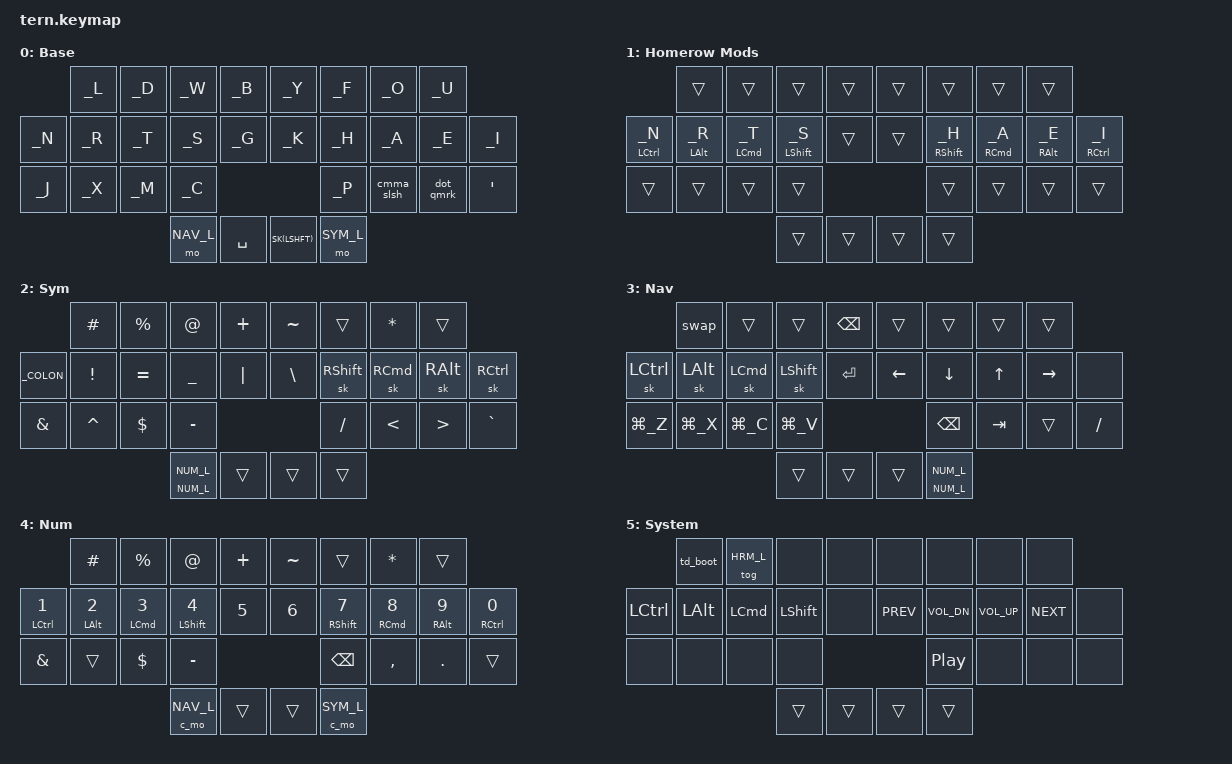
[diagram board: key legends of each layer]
/*
 * Copyright (c) 2022 The ZMK Contributors
 *
 * SPDX-License-Identifier: MIT
 */

#include <behaviors.dtsi>
#include <dt-bindings/zmk/keys.h>

// https://github.com/urob/zmk-auto-layer
#include <behaviors/num_word.dtsi>
&num_word {
  ignore-modifiers;
};

// Use Vallium layout but map it in the OS
#ifndef KEYMAP_DRAWER
#include "locales/keys_vallium.h"
#endif

/* Key positions
    0  1  2  3         4  5  6  7
8  9  10 11 12        13 14 15 16 17
18 19 20 21              22 23 24 25
            26 27  28 29            */

#define KEYS_L 0 1 2 3 8 9 10 11 12 18 19 20 21
#define KEYS_R 4 5 6 7 13 14 15 16 17 22 23 24 25
#define KEYS_T 26 27 28 29

#define DEF_L 0
#define HRM_L 1
#define SYM_L 2
#define NAV_L 3
#define NUM_L 4
#define SYS_L 5

#define NON_SYS_LAYERS DEF_L HRM_L SYM_L NAV_L NUM_L

// How long a key must be pressed to trigger Hold behavior
#define HRM_TERM 280
// If you press a tapped hold-tap again within quick-tap-ms milliseconds of the
// first press, it will always trigger the tap behavior
#define HRM_QUICK_TAP 175
// This effectively disables the hold-tap when typing quickly. As a rule of
// thumb, you want to set it to at least 10500/x where x is your (relaxed) WPM
#define HRM_IDLE (10500 / 50)
#define COMBO_IDLE HRM_IDLE

// Not-so-sticky key, see nk behavior def below
#define SK(KEY) &nk KEY KEY

// Exits num-word
#define CANCEL &kp K_CANCEL

// &lt { flavor = "tap-preferred"; };

&sk {  // sticky-key config
    release-after-ms = <900>;  // release after 0.6s
    quick-release;             // no double capitalization when rolling keys
};

/ {
    behaviors {
        hml: homerow_mods_left {
            compatible = "zmk,behavior-hold-tap";
            #binding-cells = <2>;
            flavor = "balanced";
            tapping-term-ms = <HRM_TERM>;
            quick-tap-ms = <HRM_QUICK_TAP>;
            require-prior-idle-ms = <HRM_IDLE>;
            bindings = <&kp>, <&kp>;
            hold-trigger-key-positions = <KEYS_R KEYS_T>;
            hold-trigger-on-release;             // delay positional check until key-release
        };

        hmr: homerow_mods_right {
            compatible = "zmk,behavior-hold-tap";
            #binding-cells = <2>;
            flavor = "balanced";
            tapping-term-ms = <HRM_TERM>;
            quick-tap-ms = <HRM_QUICK_TAP>;
            require-prior-idle-ms = <HRM_IDLE>;
            bindings = <&kp>, <&kp>;
            hold-trigger-key-positions = <KEYS_L KEYS_T>;
            hold-trigger-on-release;             // delay positional check until key-release
        };

        // Sticky key on tap, normal key on hold
        // Useful for modifier-clicking without the modifier remaining active
        // like in drawing applications
        nk: not_so_sticky_key {
            compatible = "zmk,behavior-hold-tap";
            #binding-cells = <2>;
            tapping_term_ms = <250>;
            flavor = "tap-preferred";
            bindings = <&kp>, <&sk>;
        };

        cmma_slsh: comma_slash {
            compatible = "zmk,behavior-mod-morph";
            #binding-cells = <0>;
            bindings = <&kp COMMA>, <&kp FSLH>;
            mods = <(MOD_LSFT|MOD_RSFT)>;
            keep-mods = <(MOD_RSFT)>;
        };

        dot_qmrk: dot_question_mark {
            compatible = "zmk,behavior-mod-morph";
            #binding-cells = <0>;
            bindings = <&kp PERIOD>, <&kp QMARK>;
            mods = <(MOD_LSFT|MOD_RSFT)>;
            keep-mods = <(MOD_RSFT)>;
        };

        td_boot: double_tap_bootloader {
            compatible = "zmk,behavior-tap-dance";
            #binding-cells = <0>;
            tapping-term-ms = <200>;
            bindings = <&none>, <&bootloader>;
        };

        swap: swapper {
            compatible = "zmk,behavior-tri-state";
            #binding-cells = <0>;
            bindings = <&kt LCMD>, <&kp TAB>, <&kt LCMD>;
            // 0+1 are the Q combo, 28 is shift
            ignored-key-positions = <0 1 28>;
        };

        #define SMART_NUM &smart_num NUM_L NUM_L
        smart_num: smart_num {
            compatible = "zmk,behavior-hold-tap";
            #binding-cells = <2>;
            flavor = "balanced";
            quick-tap-ms = <HRM_QUICK_TAP>;
            tapping-term-ms = <200>;
            bindings = <&mo>, <&num_word>;
        };
    };

    /* Key positions
       0  1  2  3         4  5  6  7
    8  9  10 11 12        13 14 15 16 17
    18 19 20 21              22 23 24 25
                26 27  28 29            */
    combos {
        compatible = "zmk,combos";
        v { key-positions = <20 21>; bindings = <&kp _V>; layers = <DEF_L>; timeout-ms = <200>; };
        q { key-positions = <0 1>;   bindings = <&kp _Q>; layers = <DEF_L>; timeout-ms = <75>; require-prior-idle-ms = <75>; };
        z { key-positions = <19 20>; bindings = <&kp _Z>; layers = <DEF_L>; timeout-ms = <200>; };

        vlbkt { key-positions = <0 9>;  bindings = <&kp LBKT>; layers = <NON_SYS_LAYERS>; require-prior-idle-ms = <COMBO_IDLE>; };
        vlpar { key-positions = <1 10>; bindings = <&kp LPAR>; layers = <NON_SYS_LAYERS>; require-prior-idle-ms = <COMBO_IDLE>; };
        vlbrc { key-positions = <2 11>; bindings = <&kp LBRC>; layers = <NON_SYS_LAYERS>; require-prior-idle-ms = <COMBO_IDLE>; };
        vrbrc { key-positions = <5 14>; bindings = <&kp RBRC>; layers = <NON_SYS_LAYERS>; require-prior-idle-ms = <COMBO_IDLE>; };
        vrpar { key-positions = <6 15>; bindings = <&kp RPAR>; layers = <NON_SYS_LAYERS>; require-prior-idle-ms = <COMBO_IDLE>; };
        vrbkt { key-positions = <7 16>; bindings = <&kp RBKT>; layers = <NON_SYS_LAYERS>; require-prior-idle-ms = <COMBO_IDLE>; };

        cw  { key-positions = <18 25>; bindings = <&kp CAPSLOCK>; layers = <DEF_L>; timeout-ms = <100>; };

        esc { key-positions = <9 10 11>; bindings = <&kp ESC>; };
        ret { key-positions = <14 15 16>; bindings = <&kp RET>; };
        bsp  { key-positions = <22 23>; bindings = <&kp BSPC>;  require-prior-idle-ms = <COMBO_IDLE>; };
        semi { key-positions = <23 24>; bindings = <&kp _SEMI>; require-prior-idle-ms = <COMBO_IDLE>; };

        sall {key-positions = <19 20>; bindings = <&kp LG(_A)>; layers = <NAV_L>; };

        // slsh { key-positions = <23 24>; bindings = <&kp FSLH>; layers = <DEF_L>; };

        /* Activate system layer on inner thumb press */
        sys { key-positions = <27 28>; bindings = <&mo SYS_L>; require-prior-idle-ms = <HRM_IDLE>; };
    };

    macros {
      ZMK_MACRO(rf_arr, bindings = <&kp EQUAL &kp GT>;)
      ZMK_MACRO(rs_arr, bindings = <&kp MINUS &kp GT>;)
      ZMK_MACRO(lf_arr, bindings = <&kp LT &kp EQUAL>;)
      ZMK_MACRO(ls_arr, bindings = <&kp LT &kp MINUS>;)
      ZMK_MACRO(expipe, bindings = <&kp PIPE &kp GT &kp SPACE>;)
      ZMK_MACRO(eextag, bindings = <&kp LT &kp PRCNT &kp EQUAL &kp SPACE &kp SPACE &kp PRCNT &kp GT &kp LEFT &kp LEFT &kp LEFT>;)

      // Cancels the num-word sticky layer, then activates the given layer
      c_mo: cancel_mo {
          compatible = "zmk,behavior-macro-one-param";
          wait-ms = <0>;
          tap-ms = <0>;
          #binding-cells = <1>;
          bindings
              = <&macro_tap &kp K_CANCEL>
              , <&macro_param_1to1>
              , <&macro_press &mo MACRO_PLACEHOLDER>
              , <&macro_pause_for_release>
              , <&macro_param_1to1>
              , <&macro_release &mo MACRO_PLACEHOLDER>
              ;
      };
    };

    keymap {
        compatible = "zmk,keymap";

        /* Mostly Gallium-v2 but without B on pinky, from:
           https://www.reddit.com/r/KeyboardLayouts/comments/15zu2rn/sturdy_vs_nerps/jxjq139/ */

        default_layer {
            display-name = "Base";
            bindings = <
                              &kp _L       &kp _D        &kp _W          &kp _B        &kp _Y           &kp _F          &kp _O       &kp _U
                &kp _N        &kp _R       &kp _T        &kp _S          &kp _G        &kp _K           &kp _H          &kp _A       &kp _E       &kp _I
                &kp _J        &kp _X       &kp _M        &kp _C                                         &kp _P          &cmma_slsh   &dot_qmrk    &kp SQT
                                                         &mo NAV_L       &kp SPACE     SK(LSHFT)        &mo SYM_L
            >;
        };

        /* The idea here is to activate this when using Illustrator/Photoshop */
        homerow_mods_layer {
            display-name = "Homerow Mods";
            bindings = <
                              &trans       &trans        &trans          &trans        &trans           &trans          &trans       &trans
                &hml LCTRL _N &hml LALT _R &hml LCMD _T  &hml LSHFT _S   &trans        &trans           &hml RSHFT _H   &hmr RCMD _A &hmr RALT _E &hmr RCTRL _I
                &trans        &trans       &trans        &trans                                         &trans          &trans       &trans       &trans
                                                         &trans          &trans        &trans           &trans
            >;
        };

        sym_layer {
            display-name = "Sym";
            bindings = <
                           &kp HASH   &kp PRCNT   &kp AT          &kp PLUS      &kp TILDE       &trans         &kp STAR    &trans     
                &kp _COLON &kp EXCL   &kp EQUAL   &kp UNDER       &kp PIPE      &kp BSLH        &sk RSHFT      &sk RCMD    &sk RALT   &sk RCTRL
                &kp AMPS   &kp CARET  &kp DLLR    &kp MINUS                                     &kp FSLH       &kp LT      &kp GT     &kp GRAVE
                                                  SMART_NUM       &trans        &trans          &trans
            >;
        };

        nav_layer {
            display-name = "Nav";
            bindings = <
                            &swap       &trans       &trans          &kp BSPC        &trans   &trans         &trans      &trans
                &sk LCTRL   &sk LALT    &sk LCMD     &sk LSHFT       &kp RET         &kp LEFT &kp DOWN       &kp UP      &kp RIGHT  &none
                &kp LG(_Z)  &kp LG(_X)  &kp LG(_C)   &kp LG(_V)                               &kp BSPC       &kp TAB     &trans     &kp FSLH
                                                     &trans          &trans          &trans   SMART_NUM
            >;
        };

        num_layer {
            display-name = "Num";
            bindings = <
                              &kp HASH     &kp PRCNT    &kp AT        &kp PLUS      &kp TILDE &trans        &kp STAR     &trans
                &hml LCTRL N1 &hml LALT N2 &hml LCMD N3 &hml LSHFT N4 &kp N5        &kp N6    &hmr RSHFT N7 &hmr RCMD N8 &hmr RALT N9 &hmr RCTRL N0
                &kp AMPS      &trans       &kp DLLR     &kp MINUS                             &kp BSPC      &kp COMMA    &kp PERIOD   &trans
                                                        &c_mo NAV_L   &trans        &trans    &c_mo SYM_L
            >;
        };

        system_layer {
            display-name = "System";
            bindings = <
                           &td_boot   &tog HRM_L &none     &none          &none           &none           &none        &none
                &kp LCTRL  &kp LALT   &kp LCMD   &kp LSHFT &none          &kp C_PREV      &kp C_VOL_DN    &kp C_VOL_UP &kp C_NEXT &none
                &none      &none      &none      &none                                    &kp C_PP        &none        &none      &none
                                                 &trans    &trans         &trans          &trans
            >;
        };
    };
};
